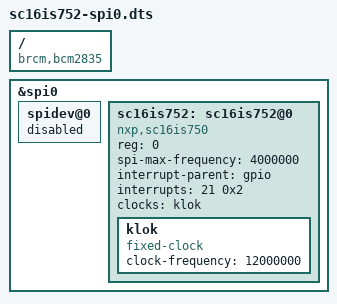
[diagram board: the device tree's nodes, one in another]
// Definitions for CANDY-Pi Board SC16IS750 UART on spi0.0
/dts-v1/;
/plugin/;

/ {
    compatible = "brcm,bcm2835", "brcm,bcm2708", "brcm,bcm2709";
    /* disable spi-dev for spi0.0 */
    fragment@0 {
        target = <&spi0>;
        __overlay__ {
            status = "okay";
            spidev@0{
                status = "disabled";
            };
        };
    };

   fragment@1 {
      target = <&spi0>;
      __overlay__ {
         #address-cells = <1>;
         #size-cells = <0>;
         status = "okay";

         sc16is752: sc16is752@0 {
            compatible = "nxp,sc16is750";
            reg = <0>; /* CE0 */
            spi-max-frequency = <4000000>;
            interrupt-parent = <&gpio>;
            interrupts = <21 0x2>; /* gpio 21, falling edge */
            clocks = <&klok>;

            klok: klok {
               compatible = "fixed-clock";
               #clock-cells = <0>;
               clock-frequency = <12000000>;
            };
         };
      };
   };
};
